VERSION ""

NS_ :

BS_:
BU_: CMU0 BMS
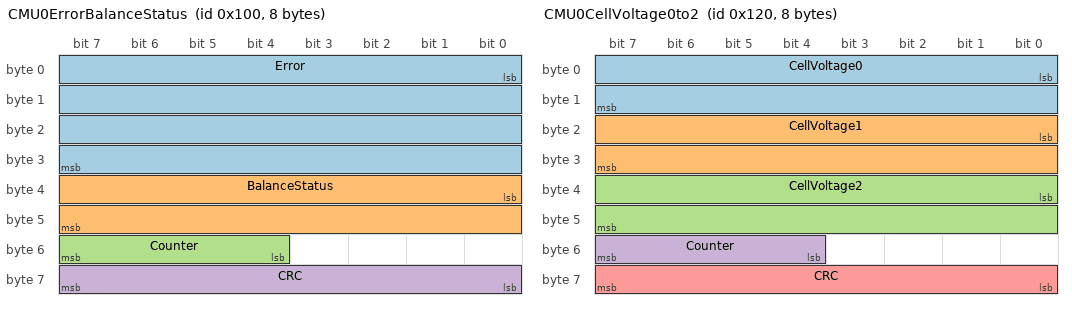
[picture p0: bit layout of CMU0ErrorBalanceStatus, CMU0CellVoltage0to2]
BO_ 256 CMU0ErrorBalanceStatus: 8 CMU0
   SG_ Error : 0|32@1+ (1,0) [0|1] "" BMS
   SG_ BalanceStatus : 32|16@1+ (1,0) [0|1] "" BMS
   SG_ Counter : 52|4@1+ (1,0) [0|1] "" BMS
   SG_ CRC : 56|8@1+ (1,0) [0|1] "" BMS

BO_ 288 CMU0CellVoltage0to2: 8 CMU0
   SG_ CellVoltage0 : 0|16@1+ (0.001,0) [0|5] "V" BMS
   SG_ CellVoltage1 : 16|16@1+ (0.001,0) [0|5] "V" BMS
   SG_ CellVoltage2 : 32|16@1+ (0.001,0) [0|5] "V" BMS
   SG_ Counter : 52|4@1+ (1,0) [0|1] "" BMS
   SG_ CRC : 56|8@1+ (1,0) [0|1] "" BMS

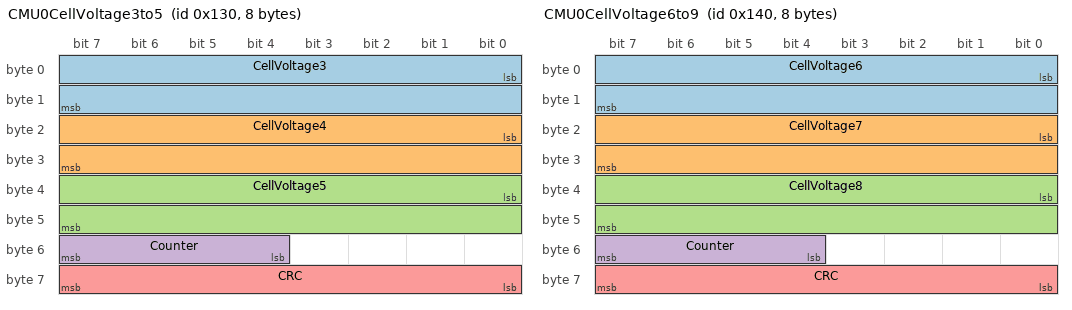
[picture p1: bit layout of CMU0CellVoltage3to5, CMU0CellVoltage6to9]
BO_ 304 CMU0CellVoltage3to5: 8 CMU0
   SG_ CellVoltage3 : 0|16@1+ (0.001,0) [0|5] "V" BMS
   SG_ CellVoltage4 : 16|16@1+ (0.001,0) [0|5] "V" BMS
   SG_ CellVoltage5 : 32|16@1+ (0.001,0) [0|5] "V" BMS
   SG_ Counter : 52|4@1+ (1,0) [0|1] "" BMS
   SG_ CRC : 56|8@1+ (1,0) [0|1] "" BMS

BO_ 320 CMU0CellVoltage6to9: 8 CMU0
   SG_ CellVoltage6 : 0|16@1+ (0.001,0) [0|5] "V" BMS
   SG_ CellVoltage7 : 16|16@1+ (0.001,0) [0|5] "V" BMS
   SG_ CellVoltage8 : 32|16@1+ (0.001,0) [0|5] "V" BMS
   SG_ Counter : 52|4@1+ (1,0) [0|1] "" BMS
   SG_ CRC : 56|8@1+ (1,0) [0|1] "" BMS

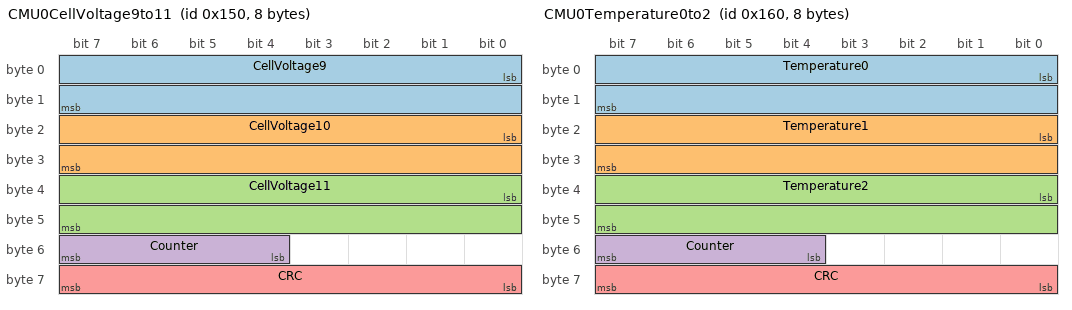
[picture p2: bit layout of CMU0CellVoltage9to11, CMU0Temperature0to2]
BO_ 336 CMU0CellVoltage9to11: 8 CMU0
   SG_ CellVoltage9 : 0|16@1+ (0.001,0) [0|5] "V" BMS
   SG_ CellVoltage10 : 16|16@1+ (0.001,0) [0|5] "V" BMS
   SG_ CellVoltage11 : 32|16@1+ (0.001,0) [0|5] "V" BMS
   SG_ Counter : 52|4@1+ (1,0) [0|1] "" BMS
   SG_ CRC : 56|8@1+ (1,0) [0|1] "" BMS

BO_ 352 CMU0Temperature0to2: 8 CMU0
   SG_ Temperature0 : 0|16@1- (0.01,0) [0|1] "°C" BMS
   SG_ Temperature1 : 16|16@1- (0.01,0) [0|1] "°C" BMS
   SG_ Temperature2 : 32|16@1- (0.01,0) [0|1] "°C" BMS
   SG_ Counter : 52|4@1+ (1,0) [0|1] "" BMS
   SG_ CRC : 56|8@1+ (1,0) [0|1] "" BMS

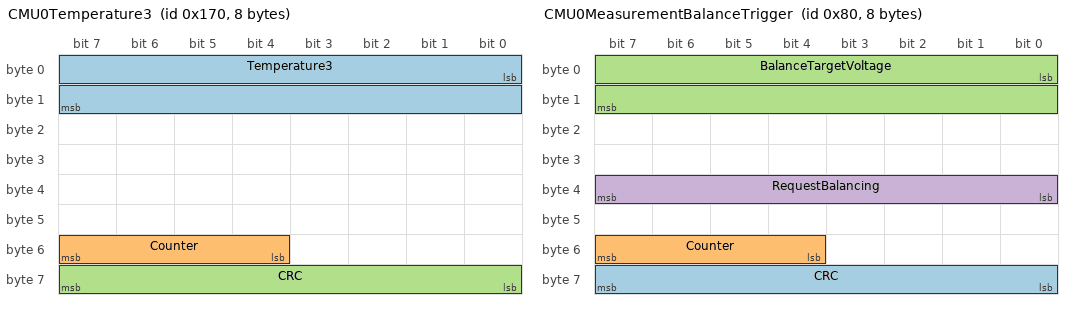
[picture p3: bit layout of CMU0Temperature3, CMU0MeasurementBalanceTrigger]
BO_ 368 CMU0Temperature3: 8 CMU0
   SG_ Temperature3 : 0|16@1- (0.01,0) [0|1] "°C" BMS
   SG_ Counter : 52|4@1+ (1,0) [0|1] "" BMS
   SG_ CRC : 56|8@1+ (1,0) [0|1] "" BMS

BO_ 272 CMU0Msg110: 8 CMU0

BO_ 384 CMU0Msg180: 8 CMU0

BO_ 128 CMU0MeasurementBalanceTrigger: 8 BMS
   SG_ CRC : 56|8@1+ (1,0) [0|1] "" CMU0
   SG_ Counter : 52|4@1+ (1,0) [0|1] "" CMU0
   SG_ BalanceTargetVoltage : 0|16@1+ (0.001,0) [0|1] "V" CMU0
   SG_ RequestBalancing : 32|8@1+ (1,0) [0|1] "" CMU0

BA_DEF_ BO_ "GenMsgBackgroundColor" STRING ;
BA_DEF_ BO_ "GenMsgForegroundColor" STRING ;
BA_DEF_DEF_ "GenMsgBackgroundColor" "#ffffff";
BA_DEF_DEF_ "GenMsgForegroundColor" "#000000";
CM_ BO_ 256 "50ms";
CM_ BO_ 288 "100ms";
CM_ BO_ 304 "100ms";
CM_ BO_ 320 "100ms";
CM_ BO_ 336 "100ms";
CM_ BO_ 352 "100ms";
CM_ BO_ 368 "100ms";
CM_ BO_ 272 "100ms";
CM_ BO_ 384 "100ms";
VAL_ 352 Temperature0 0 "No Description";
VAL_ 128 RequestBalancing 8 "Activate_Balancing" 0 "Deactivate_Balancing";
